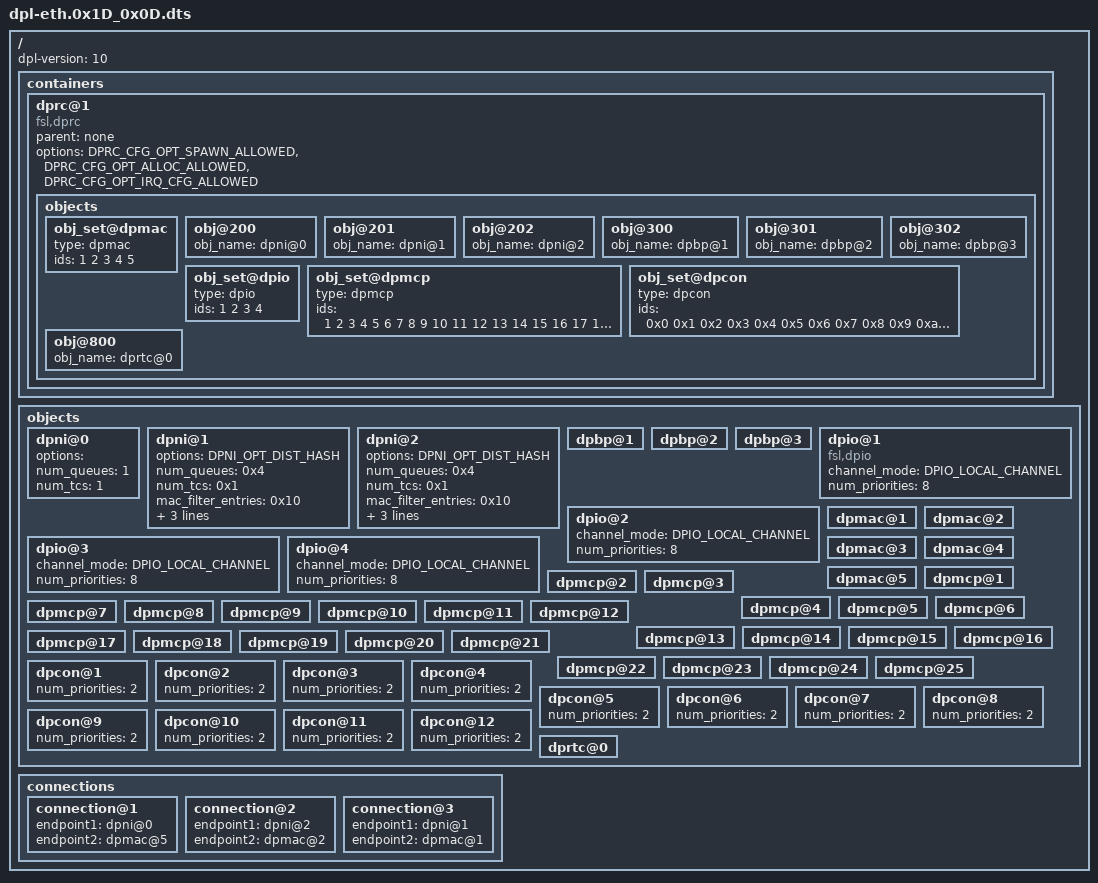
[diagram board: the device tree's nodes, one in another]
/*
 * Copyright 2016 Freescale Semiconductor, Inc.
 * Copyright 2017 NXP
 *
 * Redistribution and use in source and binary forms, with or without
 * modification, are permitted provided that the following conditions are met:
 *   * Redistributions of source code must retain the above copyright
 *     notice, this list of conditions and the following disclaimer.
 *   * Redistributions in binary form must reproduce the above copyright
 *     notice, this list of conditions and the following disclaimer in the
 *     documentation and/or other materials provided with the distribution.
 *   * Neither the name of the above-listed copyright holders nor the
 *     names of any contributors may be used to endorse or promote products
 *     derived from this software without specific prior written permission.
 *
 * THIS SOFTWARE IS PROVIDED BY THE COPYRIGHT HOLDERS AND CONTRIBUTORS "AS IS"
 * AND ANY EXPRESS OR IMPLIED WARRANTIES, INCLUDING, BUT NOT LIMITED TO, THE
 * IMPLIED WARRANTIES OF MERCHANTABILITY AND FITNESS FOR A PARTICULAR PURPOSE
 * ARE DISCLAIMED. IN NO EVENT SHALL THE COPYRIGHT HOLDERS OR CONTRIBUTORS BE
 * LIABLE FOR ANY DIRECT, INDIRECT, INCIDENTAL, SPECIAL, EXEMPLARY, OR
 * CONSEQUENTIAL DAMAGES (INCLUDING, BUT NOT LIMITED TO, PROCUREMENT OF
 * SUBSTITUTE GOODS OR SERVICES; LOSS OF USE, DATA, OR PROFITS; OR BUSINESS
 * INTERRUPTION) HOWEVER CAUSED AND ON ANY THEORY OF LIABILITY, WHETHER IN
 * CONTRACT, STRICT LIABILITY, OR TORT (INCLUDING NEGLIGENCE OR OTHERWISE)
 * ARISING IN ANY WAY OUT OF THE USE OF THIS SOFTWARE, EVEN IF ADVISED OF THE
 * POSSIBILITY OF SUCH DAMAGE.
 */

/*
 * "Bootstrap DPL" for ls1088a featuring SerDes 0x1D_0x0D.
 * This together with the available DPMCP objects should be enough to boot Linux
 * and to allow the dynamic addition of other objects to the Linux container,
 * using the 'restool' utility.
 */
/dts-v1/;
/ {
	dpl-version = <10>;
	/*****************************************************************
	 * Containers
	 *****************************************************************/
	containers {
		dprc@1 {
			compatible = "fsl,dprc";
			parent = "none";
			options = "DPRC_CFG_OPT_SPAWN_ALLOWED" , "DPRC_CFG_OPT_ALLOC_ALLOWED", "DPRC_CFG_OPT_IRQ_CFG_ALLOWED";
			objects {
				/* ------------- MACs --------------*/
				obj_set@dpmac {
					type = "dpmac";
					ids = <1 2 3 4 5>;
				};

				/* ------------ DPNIs --------------*/
				obj@200 {
					obj_name = "dpni@0";
				};
				obj@201 {
					obj_name = "dpni@1";
				};
				obj@202 {
					obj_name = "dpni@2";
				};

				/* ------------ DPBPs --------------*/
				obj@300 {
					obj_name="dpbp@1";
				};
				obj@301 {
					obj_name="dpbp@2";
				};
				obj@302 {
					obj_name="dpbp@3";
				};

				/* ------------ DPIOs --------------*/
				obj_set@dpio {
					type = "dpio";
					ids = <1 2 3 4>;
				};

				/* ------------ DPMCPs --------------*/
				obj_set@dpmcp {
					type = "dpmcp";
					ids = <1 2 3 4 5 6 7 8 9 10 11 12 13 14 15 16 17 18 19 20 21 22 23 24 25>;
				};

				/* ------------ DPCON --------------*/
				obj_set@dpcon {
					type = "dpcon";
					ids = <0x0 0x1 0x2 0x3 0x4 0x5 0x6 0x7 0x8 0x9 0xa 0xb>;
				};

				/* ------------ DPRTC --------------*/
				obj@800 {
					obj_name="dprtc@0";
				};
			};
		};
	};

	/*****************************************************************
	 * Objects
	 *****************************************************************/
	objects {

		/* ------------ DPNI --------------*/
		dpni@0 {
			options = "";
			num_queues = <1>;
			num_tcs = <1>;
		};
		dpni@1 {
			options = "DPNI_OPT_DIST_HASH";
			num_queues = <0x4>;
			num_tcs = <0x1>;
			mac_filter_entries = <0x10>;
			vlan_filter_entries = <0x0>;
			fs_entries = <0x12>;
			qos_entries = <0x0>;
		};
		dpni@2 {
			options = "DPNI_OPT_DIST_HASH";
			num_queues = <0x4>;
			num_tcs = <0x1>;
			mac_filter_entries = <0x10>;
			vlan_filter_entries = <0x0>;
			fs_entries = <0x12>;
			qos_entries = <0x0>;
		};

		/* ------------ DPBP --------------*/
		dpbp@1 {
		};
		dpbp@2 {
		};
		dpbp@3 {
		};

		/* ------------ DPIO --------------*/
		dpio@1 {
			compatible = "fsl,dpio";
			channel_mode = "DPIO_LOCAL_CHANNEL";
			num_priorities = <8>;
		};
		dpio@2 {
			channel_mode = "DPIO_LOCAL_CHANNEL";
			num_priorities = <8>;
		};
		dpio@3 {
			channel_mode = "DPIO_LOCAL_CHANNEL";
			num_priorities = <8>;
		};
		dpio@4 {
			channel_mode = "DPIO_LOCAL_CHANNEL";
			num_priorities = <8>;
		};

		/* ------------ DPMAC --------------*/
		dpmac@1 {
		};
		dpmac@2 {
		};
		dpmac@3 {
		};
		dpmac@4 {
		};
		dpmac@5 {
		};

		/* ------------ DPMCP --------------*/
		dpmcp@1 {
		};
		dpmcp@2 {
		};
		dpmcp@3 {
		};
		dpmcp@4 {
		};
		dpmcp@5 {
		};
		dpmcp@6 {
		};
		dpmcp@7 {
		};
		dpmcp@8 {
		};
		dpmcp@9 {
		};
		dpmcp@10 {
		};
		dpmcp@11 {
		};
		dpmcp@12 {
		};
		dpmcp@13 {
		};
		dpmcp@14 {
		};
		dpmcp@15 {
		};
		dpmcp@16 {
		};
		dpmcp@17 {
		};
		dpmcp@18 {
		};
		dpmcp@19 {
		};
		dpmcp@20 {
		};
		dpmcp@21 {
		};
		dpmcp@22 {
		};
		dpmcp@23 {
		};
		dpmcp@24 {
		};
		dpmcp@25 {
		};

		/* ------------ DPCON --------------*/
		dpcon@1 {
			num_priorities=<2>;
		};
		dpcon@2 {
			num_priorities=<2>;
		};
		dpcon@3 {
			num_priorities=<2>;
		};
		dpcon@4 {
			num_priorities=<2>;
		};
		dpcon@5 {
			num_priorities=<2>;
		};
		dpcon@6 {
			num_priorities=<2>;
		};
		dpcon@7 {
			num_priorities=<2>;
		};
		dpcon@8 {
			num_priorities=<2>;
		};
		dpcon@9 {
			num_priorities=<2>;
		};
		dpcon@10 {
			num_priorities=<2>;
		};
		dpcon@11 {
			num_priorities=<2>;
		};
		dpcon@12 {
			num_priorities=<2>;
		};

		/* ------------ DPRTC --------------*/
		dprtc@0 {
		};
	};

	/*****************************************************************
	 * Connections
	 *****************************************************************/
	connections {
		connection@1{
			endpoint1 = "dpni@0";
			endpoint2 = "dpmac@5";
		};
		connection@2{
			endpoint1 = "dpni@2";
			endpoint2 = "dpmac@2";
		};
		connection@3{
			endpoint1 = "dpni@1";
			endpoint2 = "dpmac@1";
		};
	};
};
